# YTM32B1MD1 register map
Vendor: YTMicro; File version: 1.0
CPU: CM33 r0p4, little endian, MPU, FPU, 2 interrupt priority bits
Registers are 32-bit, read-write, reset 0x0 unless marked. A register's access mark holds for its fields unless they carry their own. Offsets are from the block's base; [hi:lo] are bit positions.

## PCU — Power control unit
Base 0x4007E000; register names take the prefix PCU_
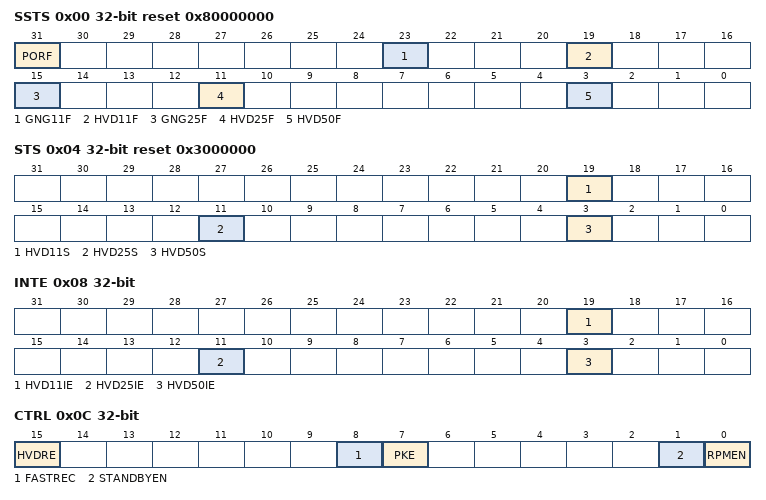
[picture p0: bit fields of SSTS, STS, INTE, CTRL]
0x00 SSTS reset 0x80000000
  [31] PORF — Flags that a power on reset event has occurred. Writing 1 clears it. Other reset sources have no effect.
    0=No power-on reset event has occurred; 1=Power-on reset event has occurred
  [23] GNG11F — Flags that the Go/NoGo sensor has detected a low voltage on the V11 domain in FPM. This applies to only to the part of the domain that supplies the 1.1V clocking modules (e.g. FIRC, SIRC). Writing 1 clears it. Other reset sources have no effect.
    0=No event has occurred; 1=NoGo event has occurred
  [19] HVD11F — This ready-only status bit indicates a high voltage detect event on VDD11. Write 1 to clear this bit.
    0=High voltage event on VDD11 not detected; 1=High voltage event on VDD11 detected
  [15] GNG25F — Flags that the Go/NoGo sensor has detected a low voltage on the V25 domain in FPM. This applies to only to the part of the domain that supplies the 2.5V clocking modules (e.g. FXOSC, PLL). Writing 1 clears it. Other reset sources have no effect.
    0=No event has occurred; 1=NoGo event has occurred
  [11] HVD25F — This ready-only status bit indicates a high voltage detect event on VDD25. Write 1 to clear this bit.
    0=High voltage event on VDD25 not detected; 1=High voltage event on VDD25 detected
  [3] HVD50F — This ready-only status bit indicates a high voltage detect event on VDD. Write 1 to clear this bit.
    0=High voltage event on VDD not detected; 1=High voltage event on VDD detected
0x04 STS reset 0x3000000
  [19] HVD11S ro — Shows the status of the high voltage detect on VDD11 power domain.
    0=Voltage on VDD11 is below high-voltage detect threshold; 1=Voltage on VDD11 is above high-voltage detect threshold
  [11] HVD25S ro — Shows the status of the high voltage detect on VDD25 power domain.
    0=Voltage on VDD25 is below high-voltage detect threshold; 1=Voltage on VDD25 is above high-voltage detect threshold
  [3] HVD50S ro — Shows the status of the high voltage detect on VDD power domain.
    0=Voltage on VDD is below high-voltage detect threshold; 1=Voltage on VDD is above high-voltage detect threshold
0x08 INTE
  [19] HVD11IE — This bit enables hardware interrupt requests if HVD11F is set.
    0=HVD hardware interrupt is disabled (use polling); 1=Request a HVD hardware interrupt when HVD11F=1
  [11] HVD25IE — This bit enables hardware interrupt requests if HVD25F is set.
    0=HVD hardware interrupt is disabled (use polling); 1=Request a HVD hardware interrupt when HVD25F=1
  [3] HVD50IE — This bit enables hardware interrupt requests if HVD50F is set.
    0=HVD hardware interrupt is disabled (use polling); 1=Request a HVD hardware interrupt when HVD50F=1
0x0C CTRL
  [15] HVDRE — This bit controls whether high voltage detect event generates a reset.
    0=Don't generate reset when a high voltage detect event occurs; 1=Generate reset when a high voltage detect event occurs
  [8] FASTREC — This bit controls the recovery time from Low Power Mode (LPM) to Full Performance Mode (FPM). At recovery from Low Power Mode all the tank capacitors from the secondary supplies have to re recharged. This causes a high current demand, that might not be met by the supply driving the VDD primary domain. When selecting the fast recovery time, the current for recharging is approximately 3 times higher than for FASTREC=0.
    0=Normal recovery time from LPM; 1=Fast recovery time from LPM
  [7] PKE — This bit is to control PAD state when wakeup from power mode.
    0=PAD state is reseted when wakeup from Powerdown mode; 1=PAD state is kept when wakeup from Powerdown mode until PKE bit is cleared to 0. ewline Note: If Powerdown mode is waken up by reset pin, PAD state is always reseted.
  [1] STANDBYEN — This bit forces pmc to enter standby mode.
    0=Disable standby mode entry; 1=Enable standby mode entry
  [0] RPMEN — This bit controls the reduce performance mode entry or not.
    0=Disable RPM entry; 1=Enable RPM entry
